# C7X256V_CORE0_C7XV_256_UMC_CFG_7C000000h register map
Vendor: Texas Instruments
Peripheral module from a debugger description file (folder am62D).
Registers are 32-bit, access per field, reset values left out (the file's numbers can be read two ways) unless marked. A register's access mark holds for its fields unless they carry their own. Offsets are as the file gives them; lines under a group give offsets from that group; [hi:lo] are bit positions; {n}, {i} and the like mark numbered series; 'fields as' and 'values as' point back to an identical list; <NAME> marks a mode.

## c7xv_256_umc_cfg
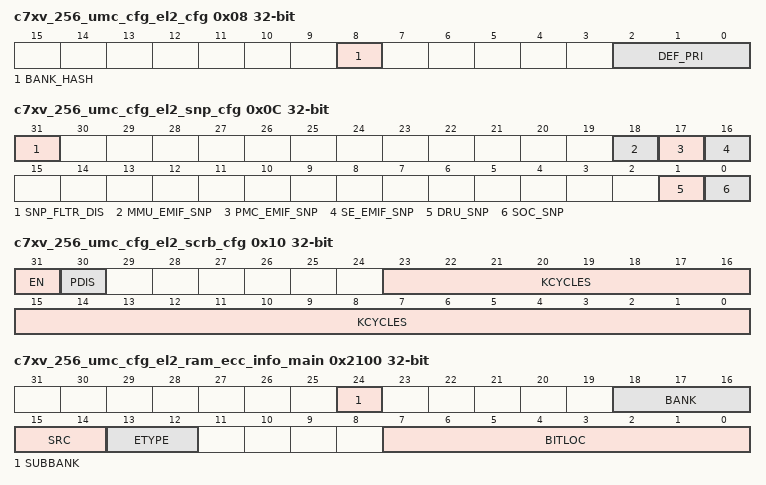
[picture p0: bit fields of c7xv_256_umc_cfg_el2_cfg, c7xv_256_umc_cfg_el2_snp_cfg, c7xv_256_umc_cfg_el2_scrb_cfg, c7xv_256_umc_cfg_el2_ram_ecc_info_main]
0x08 c7xv_256_umc_cfg_el2_cfg — General Operation Configuration Register
  [8] BANK_HASH rw — When set, the bank which will be accessed will be determined by the address hashing algorithm. When clear, the bank which will be accessed will come from the address bits 7 through 5 Reset Source: c7xv_core_rst
  [2:0] DEF_PRI rw — Priority value that is assigned for Patrons which do not have a cpriority signal on their command bus. Mainly used by internal c7x Patrons Reset Source: c7xv_core_rst
0x0C c7xv_256_umc_cfg_el2_snp_cfg — Snoop Configuration Register
  [31] SNP_FLTR_DIS rw — When set, the snoop filter will be disabled. When clear, the snoop filter performs it's specified operations Reset Source: c7xv_core_rst
  [18] MMU_EMIF_SNP rw — When set, MMU reads to EMIF space will generate a CleanInvalid snoop to DMC on MMU reads. When clear, MMU reads will not generate a snoop to DMC Reset Source: c7xv_core_rst
  [17] PMC_EMIF_SNP rw — When set, PMC reads to EMIF space will generate a CleanInvalid snoop to DMC on PMC reads. When clear, PMC reads will not generate a snoop to DMC Reset Source: c7xv_core_rst
  [16] SE_EMIF_SNP rw — When set, Streaming Engine reads to EMIF space will generate a CleanInvalid snoop to DMC on SE reads. When clear, SE reads will not generate a snoop to DMC Reset Source: c7xv_core_rst
  [1] DRU_SNP rw — When set, DRU writes to the internal SRAM will generate a MakeInvalid snoop to DMC. When clear, DRU writes will not generate a snoop to DMC Reset Source: c7xv_core_rst
  [0] SOC_SNP rw — When set, SoC writes to the internal SRAM will generate a MakeInvalid snoop to DMC. When clear, SoC writes will not generate a snoop to DMC Reset Source: c7xv_core_rst
0x10 c7xv_256_umc_cfg_el2_scrb_cfg — ECC Scrubber Configuration Register
  [31] EN rw — When set, the scrubber is enabled. When clear, the scrubber is disabled and does not function Reset Source: c7xv_core_rst
  [30] PDIS rw — When set, the 1024 cycle prescale counter is disabled, and the number of cycles between scrub bursts will be exactly the value in the KCYCLES field. Setting this bit is expected to only be used by the hardware verification team to stress-test interaction between the scrubber and normal functional accesses Reset Source: c7xv_core_rst
  [23:0] KCYCLES rw — Number of kilocycles between scrub bursts. Specifically, there will be 1024 * KCYCLES cycles between scrub bursts delay. When set to zero, delay will be approximately 32 cycles between bursts Reset Source: c7xv_core_rst
0x1000 c7xv_256_umc_cfg_el2_sbnd_c7x — Starvation Bound for C7X
  [7:0] SBND rw — Number of cycles that the Patron request may lose arbitration before declaring that it has starved Reset Source: c7xv_core_rst
0x1004 c7xv_256_umc_cfg_el2_sbnd_soc — Starvation Bound for SoC
  fields as c7xv_256_umc_cfg_el2_sbnd_c7x
0x1008 c7xv_256_umc_cfg_el2_sbnd_dru — Starvation Bound for DRU
  fields as c7xv_256_umc_cfg_el2_sbnd_c7x
0x100C c7xv_256_umc_cfg_el2_sbnd_ihop — Starvation Bound for internal IHOPs
  fields as c7xv_256_umc_cfg_el2_sbnd_c7x
0x1800 c7xv_256_umc_cfg_el2_sbrst_c7x — Starvation Burst Count for C7X
  [7:0] SBRST rw — Maximum number of bank-to-back commands which will be marked as starvation commands from the Patron when the starvation bound counter expires Reset Source: c7xv_core_rst
0x1804 c7xv_256_umc_cfg_el2_sbrst_soc — Starvation Burst Count for SoC
  fields as c7xv_256_umc_cfg_el2_sbrst_c7x
0x1808 c7xv_256_umc_cfg_el2_sbrst_dru — Starvation Burst Count for DRU
  fields as c7xv_256_umc_cfg_el2_sbrst_c7x
0x180C c7xv_256_umc_cfg_el2_sbrst_ihop — Starvation Burst Count for internal IHOPs
  fields as c7xv_256_umc_cfg_el2_sbrst_c7x
0x2000 c7xv_256_umc_cfg_el2_ram_ecc_unc — Uncorrectable Error Count
  [15:0] COUNT rw — Records the total number of uncorrectable errors that have been detected Reset Source: c7xv_core_rst
0x2004 c7xv_256_umc_cfg_el2_ram_ecc_cor rw — Corrected Error Count
  [31:0] COUNT — Records the total number of errors that have been corrected Reset Source: c7xv_core_rst
0x2008 c7xv_256_umc_cfg_el2_ram_ecc_cor_wb — Corrected Error Count Written to SRAM
  [15:0] COUNT rw — Records the total number of errors that were corrected and written back to SRAM by the scrubber Reset Source: c7xv_core_rst
0x2100 c7xv_256_umc_cfg_el2_ram_ecc_info_main — Last ECC Error Information Register from the mem_main SRAM
  [24] SUBBANK rw — Records the sub-bank which was read that produced the error Reset Source: c7xv_core_rst
  [18:16] BANK rw — Records the bank which was read that produced the error Reset Source: c7xv_core_rst
  [15:14] SRC rw — Records whether the error was detected on a functional access or a scrub cycle 0 Error detected on functional access1 Error detected during a scrub cycle2 Error detected during an error injection cycle3 Reserved
  [13:12] ETYPE rw — Records the type of error that was detected 0 No errors have been detected1 1-bit correctable error2 2 or more bit uncorrectable error3 Reserved
  [7:0] BITLOC rw — Upon detection of an ECC error, records the location of the bit which was found to be in error for the last 1-bit correctable error that was detected within the subbank. Note that each sub-bank has 128-bits of data and 23 bits of parity and ECC information, so this value can range from 0 to 150 Reset Source: c7xv_core_rst
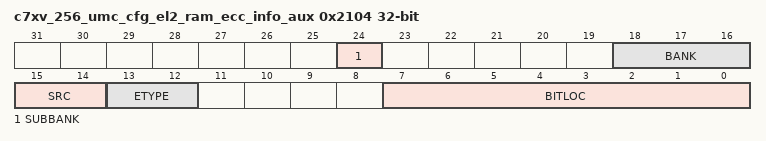
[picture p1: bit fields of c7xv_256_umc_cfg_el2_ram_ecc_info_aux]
0x2104 c7xv_256_umc_cfg_el2_ram_ecc_info_aux — Last ECC Error Information Register from the mem_aux SRAM
  fields as c7xv_256_umc_cfg_el2_ram_ecc_info_main
0x2200 c7xv_256_umc_cfg_el2_ram_ecc_addr_main — Last ECC Error SRAM Bank Address from the mem_main SRAM
  [11:0] ADDR rw — Upon detection of an ECC error, records the row address that was accessed on the SRAM with the error Reset Source: c7xv_core_rst
0x2204 c7xv_256_umc_cfg_el2_ram_ecc_addr_aux — Last ECC Error SRAM Bank Address from the mem_aux SRAM
  fields as c7xv_256_umc_cfg_el2_ram_ecc_addr_main
